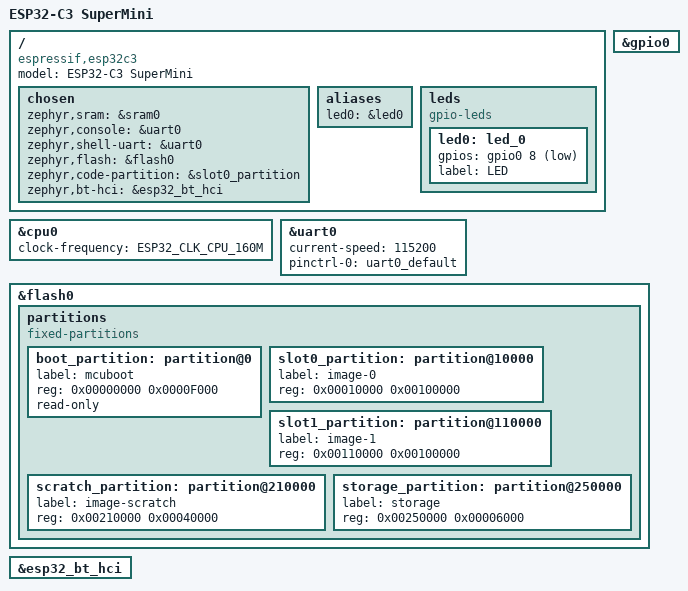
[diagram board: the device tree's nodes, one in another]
/dts-v1/;

#include <espressif/esp32c3/esp32c3_mini_n4.dtsi>
#include "esp32c3_supermini-pinctrl.dtsi"

/ {
    model = "ESP32-C3 SuperMini";
    compatible = "espressif,esp32c3";

    chosen {
        zephyr,sram = &sram0;
        zephyr,console = &uart0;
        zephyr,shell-uart = &uart0;
        zephyr,flash = &flash0;
        zephyr,code-partition = &slot0_partition;
        zephyr,bt-hci = &esp32_bt_hci;
    };

    aliases {
        led0 = &led0;
    };

    leds {
        compatible = "gpio-leds";
        led0: led_0 {
            gpios = <&gpio0 8 GPIO_ACTIVE_LOW>;
            label = "LED";
        };
    };
};

&cpu0 {
    clock-frequency = <ESP32_CLK_CPU_160M>;
};

&uart0 {
    status = "okay";
    current-speed = <115200>;
    pinctrl-0 = <&uart0_default>;
    pinctrl-names = "default";
};

&gpio0 {
    status = "okay";
};

&flash0 {
    status = "okay";
    partitions {
        compatible = "fixed-partitions";
        #address-cells = <1>;
        #size-cells = <1>;

        boot_partition: partition@0 {
            label = "mcuboot";
            reg = <0x00000000 0x0000F000>;
            read-only;
        };

        slot0_partition: partition@10000 {
            label = "image-0";
            reg = <0x00010000 0x00100000>;
        };

        slot1_partition: partition@110000 {
            label = "image-1";
            reg = <0x00110000 0x00100000>;
        };

        scratch_partition: partition@210000 {
            label = "image-scratch";
            reg = <0x00210000 0x00040000>;
        };

        storage_partition: partition@250000 {
            label = "storage";
            reg = <0x00250000 0x00006000>;
        };
    };
};

&esp32_bt_hci {
    status = "okay";
};
